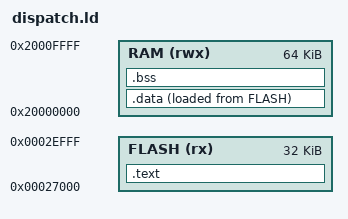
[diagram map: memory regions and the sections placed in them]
MEMORY
{
  FLASH (rx) : ORIGIN = 0x27000, LENGTH = 0x8000
  RAM (rwx) : ORIGIN = 0x20000000, LENGTH = 64K
}

SECTIONS
{
  .text : {
    KEEP(*(.isr_vector))
    *(.text*)
    *(.rodata*)
  } > FLASH

  .data : {
    *(.data*)
  } > RAM AT > FLASH

  .bss : {
    *(.bss*)
    *(COMMON)
  } > RAM
}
